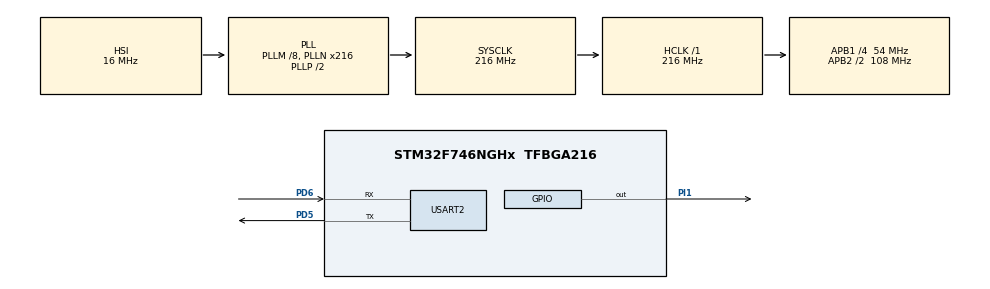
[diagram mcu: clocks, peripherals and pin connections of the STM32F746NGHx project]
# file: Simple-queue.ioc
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FREERTOS.Tasks01=defaultTask,0,128,StartDefaultTask,Default,NULL,Dynamic,NULL,NULL
Mcu.Family=STM32F7
Mcu.Name=STM32F746NGHx
Mcu.Package=TFBGA216
NVIC.PriorityGroup=NVIC_PRIORITYGROUP_4
NVIC.TIM1_UP_TIM10_IRQn=true\:15\:0\:false\:false\:true\:false\:false\:true
NVIC.TimeBase=TIM1_UP_TIM10_IRQn
NVIC.TimeBaseIP=TIM1
NVIC.USART2_IRQn=true\:5\:0\:false\:false\:true\:true\:true\:true
PA13.Mode=Serial_Wire
PA13.Signal=SYS_JTMS-SWDIO
PA14.Mode=Serial_Wire
PA14.Signal=SYS_JTCK-SWCLK
PD5.Mode=Asynchronous
PD5.Signal=USART2_TX
PD6.Mode=Asynchronous
PD6.Signal=USART2_RX
PI1.Signal=GPIO_Output
ProjectManager.HeapSize=0x200
ProjectManager.StackSize=0x400
ProjectManager.TargetToolchain=STM32CubeIDE
RCC.AHBFreq_Value=216000000
RCC.APB1CLKDivider=RCC_HCLK_DIV4
RCC.APB1Freq_Value=54000000
RCC.APB1TimFreq_Value=108000000
RCC.APB2CLKDivider=RCC_HCLK_DIV2
RCC.APB2Freq_Value=108000000
RCC.APB2TimFreq_Value=216000000
RCC.CortexFreq_Value=216000000
RCC.FLatency-AdvancedSettings=FLASH_LATENCY_7
RCC.HCLKFreq_Value=216000000
RCC.HSE_VALUE=25000000
RCC.HSI_VALUE=16000000
RCC.I2C3Enable-ClockTree=true
RCC.PLL48CLockSelection=RCC_CLK48SOURCE_PLLSAIP
RCC.PLLI2SN=100
RCC.PLLM=8
RCC.PLLN=216
RCC.PLLQ=9
RCC.PLLSAIN=384
RCC.PLLSAIP=RCC_PLLSAIP_DIV8
RCC.PLLSAIR=5
RCC.PLLSAIRDiv=RCC_PLLSAIDIVR_8
RCC.SDMMCClockSelection=RCC_SDMMC1CLKSOURCE_CLK48
RCC.SYSCLKFreq_VALUE=216000000
RCC.SYSCLKSource=RCC_SYSCLKSOURCE_PLLCLK
RCC.USBFreq_Value=96000000
RCC.VCOOutputFreq_Value=432000000
USART2.VirtualMode-Asynchronous=VM_ASYNC
VP_FREERTOS_VS_CMSIS_V1.Mode=CMSIS_V1
VP_SYS_VS_tim1.Mode=TIM1
board=STM32F746G-DISCO

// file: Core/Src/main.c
/* USER CODE BEGIN Header */
/**
  ******************************************************************************
  * @file           : main.c
  * @brief          : Main program body
  ******************************************************************************
  * @attention
  *
  * Copyright (c) 2022 STMicroelectronics.
  * All rights reserved.
  *
  * This software is licensed under terms that can be found in the LICENSE file
  * in the root directory of this software component.
  * If no LICENSE file comes with this software, it is provided AS-IS.
  *
  ******************************************************************************
  */
/* USER CODE END Header */
#include "main.h"
//#include "cmsis_os.h"
#include "FreeRTOS.h"
#include "task.h"
#include "timers.h"
#include "queue.h"
#include "semphr.h"
#include "event_groups.h"

#include "string.h"
#include "stdio.h"

UART_HandleTypeDef huart2;

//osThreadId defaultTaskHandle;

void SystemClock_Config(void);
static void MX_GPIO_Init(void);
static void MX_USART2_UART_Init(void);
//void StartDefaultTask(void const * argument);

/* USER CODE BEGIN 0 */
/**************** TASK HANDLERS ***********************/
xTaskHandle Sender_HPT_Handler;
xTaskHandle Sender_LPT_Handler;
xTaskHandle Receiver_Handler;

/**************** QUEUE HANDLER ***********************/
xQueueHandle SimpleQueue;
/**************** TASK FUNCTIONS ***********************/
void Sender_HPT_Task (void *argument);
void Sender_LPT_Task (void *argument);
void Receiver_Task (void *argument);

uint8_t Rx_data;

/* USER CODE END 0 */

int main(void)
{

  /* MCU Configuration--------------------------------------------------------*/

  /* Reset of all peripherals, Initializes the Flash interface and the Systick. */
  HAL_Init();

  /* Configure the system clock */
  SystemClock_Config();

  /* Initialize all configured peripherals */
  MX_GPIO_Init();
  MX_USART2_UART_Init();
  /* USER CODE BEGIN 2 */
  /************************* Create Integer Queue ****************************/
   SimpleQueue = xQueueCreate(5, sizeof (int)); // creation of a queue which can store 5 integers
   if (SimpleQueue == 0)  // Queue not created like there is an error
   {
 	  char *str = "Unable to create Integer Queue\n\n";
 	  HAL_UART_Transmit(&huart2, (uint8_t *)str, strlen (str), HAL_MAX_DELAY);
   }
   else
   {
 	  char *str = "Integer Queue Created successfully\n\n";
 	  HAL_UART_Transmit(&huart2, (uint8_t *)str, strlen (str), HAL_MAX_DELAY);
   }

   /****************************** TASK RELATED ******************************/

    xTaskCreate(Sender_HPT_Task, "HPT_SEND", 128, NULL, 3, &Sender_HPT_Handler);
    xTaskCreate(Sender_LPT_Task, "LPT_SEND", 128, (void *)111 , 2, &Sender_LPT_Handler);

    xTaskCreate(Receiver_Task, "Receive", 128, NULL, 1, &Receiver_Handler);

    HAL_UART_Receive_IT(&huart2, &Rx_data, 1);

    vTaskStartScheduler();
  /* USER CODE END 2 */

  /* Create the thread(s) */
  /* definition and creation of defaultTask */
//  osThreadDef(defaultTask, StartDefaultTask, osPriorityNormal, 0, 128);
//  defaultTaskHandle = osThreadCreate(osThread(defaultTask), NULL);

  /* Start scheduler */
//  osKernelStart();

  /* We should never get here as control is now taken by the scheduler */
  /* Infinite loop */
  while (1)
  {

  }
}

void SystemClock_Config(void)
{
  RCC_OscInitTypeDef RCC_OscInitStruct = {0};
  RCC_ClkInitTypeDef RCC_ClkInitStruct = {0};

  /** Configure the main internal regulator output voltage
  */
  __HAL_RCC_PWR_CLK_ENABLE();
  __HAL_PWR_VOLTAGESCALING_CONFIG(PWR_REGULATOR_VOLTAGE_SCALE1);
  /** Initializes the RCC Oscillators according to the specified parameters
  * in the RCC_OscInitTypeDef structure.
  */
  RCC_OscInitStruct.OscillatorType = RCC_OSCILLATORTYPE_HSI;
  RCC_OscInitStruct.HSIState = RCC_HSI_ON;
  RCC_OscInitStruct.HSICalibrationValue = RCC_HSICALIBRATION_DEFAULT;
  RCC_OscInitStruct.PLL.PLLState = RCC_PLL_ON;
  RCC_OscInitStruct.PLL.PLLSource = RCC_PLLSOURCE_HSI;
  RCC_OscInitStruct.PLL.PLLM = 8;
  RCC_OscInitStruct.PLL.PLLN = 216;
  RCC_OscInitStruct.PLL.PLLP = RCC_PLLP_DIV2;
  RCC_OscInitStruct.PLL.PLLQ = 9;
  if (HAL_RCC_OscConfig(&RCC_OscInitStruct) != HAL_OK)
  {
    Error_Handler();
  }
  /** Activate the Over-Drive mode
  */
  if (HAL_PWREx_EnableOverDrive() != HAL_OK)
  {
    Error_Handler();
  }
  /** Initializes the CPU, AHB and APB buses clocks
  */
  RCC_ClkInitStruct.ClockType = RCC_CLOCKTYPE_HCLK|RCC_CLOCKTYPE_SYSCLK
                              |RCC_CLOCKTYPE_PCLK1|RCC_CLOCKTYPE_PCLK2;
  RCC_ClkInitStruct.SYSCLKSource = RCC_SYSCLKSOURCE_PLLCLK;
  RCC_ClkInitStruct.AHBCLKDivider = RCC_SYSCLK_DIV1;
  RCC_ClkInitStruct.APB1CLKDivider = RCC_HCLK_DIV4;
  RCC_ClkInitStruct.APB2CLKDivider = RCC_HCLK_DIV2;

  if (HAL_RCC_ClockConfig(&RCC_ClkInitStruct, FLASH_LATENCY_7) != HAL_OK)
  {
    Error_Handler();
  }
}

static void MX_USART2_UART_Init(void)
{

  huart2.Instance = USART2;
  huart2.Init.BaudRate = 115200;
  huart2.Init.WordLength = UART_WORDLENGTH_8B;
  huart2.Init.StopBits = UART_STOPBITS_1;
  huart2.Init.Parity = UART_PARITY_NONE;
  huart2.Init.Mode = UART_MODE_TX_RX;
  huart2.Init.HwFlowCtl = UART_HWCONTROL_NONE;
  huart2.Init.OverSampling = UART_OVERSAMPLING_16;
  huart2.Init.OneBitSampling = UART_ONE_BIT_SAMPLE_DISABLE;
  huart2.AdvancedInit.AdvFeatureInit = UART_ADVFEATURE_NO_INIT;
  if (HAL_UART_Init(&huart2) != HAL_OK)
  {
    Error_Handler();
  }

}

static void MX_GPIO_Init(void)
{
  GPIO_InitTypeDef GPIO_InitStruct = {0};

  /* GPIO Ports Clock Enable */
  __HAL_RCC_GPIOA_CLK_ENABLE();
  __HAL_RCC_GPIOD_CLK_ENABLE();
  __HAL_RCC_GPIOI_CLK_ENABLE();

  /*Configure GPIO pin Output Level */
  HAL_GPIO_WritePin(GPIOI, GPIO_PIN_1, GPIO_PIN_RESET);

  /*Configure GPIO pin : PI1 */
  GPIO_InitStruct.Pin = GPIO_PIN_1;
  GPIO_InitStruct.Mode = GPIO_MODE_OUTPUT_PP;
  GPIO_InitStruct.Pull = GPIO_NOPULL;
  GPIO_InitStruct.Speed = GPIO_SPEED_FREQ_LOW;
  HAL_GPIO_Init(GPIOI, &GPIO_InitStruct);

}

/* USER CODE BEGIN 4 */
void Sender_HPT_Task (void *argument)
{
	int i=222;
	uint32_t TickDelay = pdMS_TO_TICKS(2000);
	while (1)
	{
		char *str = "Entered SENDER_HPT Task\n about to SEND a number to the queue\n\n";
		HAL_UART_Transmit(&huart2, (uint8_t *)str, strlen (str), HAL_MAX_DELAY);

		if (xQueueSend(SimpleQueue, &i, portMAX_DELAY) == pdPASS)
		{
			char *str2 = " Successfully sent the number to the queue\nLeaving SENDER_HPT Task\n\n\n";
			HAL_UART_Transmit(&huart2, (uint8_t *)str2, strlen (str2), HAL_MAX_DELAY);
		}

		vTaskDelay(TickDelay);
	}
}

void Sender_LPT_Task (void *argument)
{
	int ToSend;
	uint32_t TickDelay = pdMS_TO_TICKS(1000);
	while (1)
	{
		ToSend = (int) argument;
		char *str = "Entered SENDER_LPT Task\n about to SEND a number to the queue\n\n";
		HAL_UART_Transmit(&huart2, (uint8_t *)str, strlen (str), HAL_MAX_DELAY);

		xQueueSend(SimpleQueue, &ToSend, portMAX_DELAY);

		char *str2 = " Successfully sent the number to the queue\nLeaving SENDER_LPT Task\n\n\n";
		HAL_UART_Transmit(&huart2, (uint8_t *)str2, strlen (str2), HAL_MAX_DELAY);

		vTaskDelay(TickDelay);
	}
}

void Receiver_Task (void *argument)
{
	int received=0;
	uint32_t TickDelay = pdMS_TO_TICKS(3000);
	while (1)
	{
		char str[100];
		strcpy (str, "Entered RECEIVER Task\n about to RECEIVE a number from the queue\n\n");
		HAL_UART_Transmit(&huart2, (uint8_t *)str, strlen (str), HAL_MAX_DELAY);

		if (xQueueReceive(SimpleQueue, &received, portMAX_DELAY) != pdTRUE)
		{
			HAL_UART_Transmit(&huart2, (uint8_t *)"Error in Receiving from Queue\n\n", 31, 1000);
		}
		else
		{
			sprintf(str, " Successfully RECEIVED the number %d to the queue\nLeaving RECEIVER Task\n\n\n",received);
			HAL_UART_Transmit(&huart2, (uint8_t *)str, strlen (str), HAL_MAX_DELAY);
		}

		vTaskDelay(TickDelay);
	}
}

void HAL_UART_RxCpltCallback(UART_HandleTypeDef *huart)
{
	HAL_UART_Receive_IT(huart, &Rx_data, 1);
	int ToSend = 123456789;
	if (Rx_data == 'r')
	{
		 /* The xHigherPriorityTaskWoken parameter must be initialized to pdFALSE as
		 it will get set to pdTRUE inside the interrupt safe API function if a
		 context switch is required. */
		BaseType_t xHigherPriorityTaskWoken = pdFALSE;

		if (xQueueSendToFrontFromISR(SimpleQueue, &ToSend, &xHigherPriorityTaskWoken) == pdPASS)
		{
			HAL_UART_Transmit(huart, (uint8_t *)"\n\nSent from ISR\n\n", 17, 500);
		}

		/* Pass the xHigherPriorityTaskWoken value into portEND_SWITCHING_ISR(). If
		 xHigherPriorityTaskWoken was set to pdTRUE inside xSemaphoreGiveFromISR()
		 then calling portEND_SWITCHING_ISR() will request a context switch. If
		 xHigherPriorityTaskWoken is still pdFALSE then calling
		 portEND_SWITCHING_ISR() will have no effect */

		portEND_SWITCHING_ISR(xHigherPriorityTaskWoken);
	}
}

/* USER CODE END 4 */

//void StartDefaultTask(void const * argument)
//{
//  /* USER CODE BEGIN 5 */
//  /* Infinite loop */
//  for(;;)
//  {
//    osDelay(1);
//  }
//  /* USER CODE END 5 */
//}

void HAL_TIM_PeriodElapsedCallback(TIM_HandleTypeDef *htim)
{
  if (htim->Instance == TIM1) {
    HAL_IncTick();
  }
}

void Error_Handler(void)
{
  __disable_irq();
  while (1)
  {
  }
}
